# tviic2d6mddr register map
Vendor: Cypress Semiconductor; Series: tviic2d6mddr; File version: 1.0
CPU: CM7 r0p1, little endian, MPU, FPU, VTOR, 3 interrupt priority bits
Registers are 32-bit, read-write, reset 0x0 unless marked. A register's access mark holds for its fields unless they carry their own. Offsets are from the block's base; [hi:lo] are bit positions; lines under a group give offsets from that group; {n}, {i} and the like mark numbered series; 'fields as' and 'values as' point back to an identical list.

## VIDEOSS0 (part 6 of 18) — Video and Graphics Subsystem IP
Base 0x40A00000
0x80000 VIDEOIO group — Video I/O Core
  0x00 SUBIO group — Sub Interface
    0x10000 COMPENG group — Composition Engine
      0x2C00 EXTDST4 group — ExtDst #4 (Safety)
        0x0C STATUS — External Destination Unit current status
          [0] CNT_ERR_STS — Pixel count error
        0x10 CONTROLWORD ro reset not defined — Value of last received control word
          [31:0] CW_VAL
        0x14 CURPIXELCNT ro reset not defined — pixel count of currently running frame
          [31:16] C_YVAL — value of vertical line counter, internal counter counting from max-1 to 0
          [15:0] C_XVAL — value of horizontal pixel counter, internal counter counting from max-1 to 0
        0x18 LASTPIXELCNT ro reset not defined — pixel count between last two control words
          [31:16] L_YVAL — value of vertical line counter
          [15:0] L_XVAL — value of horizontal pixel counter
        0x1C PERFCOUNTER ro — Performance counter result
          [31:0] PERFRESULT — Returns the performance counter value. Returns number of cycles of the last frame on the input. To calculate the performance divide the known number of pixels of the frame by this number. For debug purposes only, read when stable only, otherwise read data might be corrupted.
      0x3000 CONSTFRAME1 group — ConstFrame #1 (Content)
        0x00 STATICCONTROL — ConstFrame unit static control register
          [0] SHDEN — Enables shadowing of all RWS type registers (0=write_through, 1=shadowed).
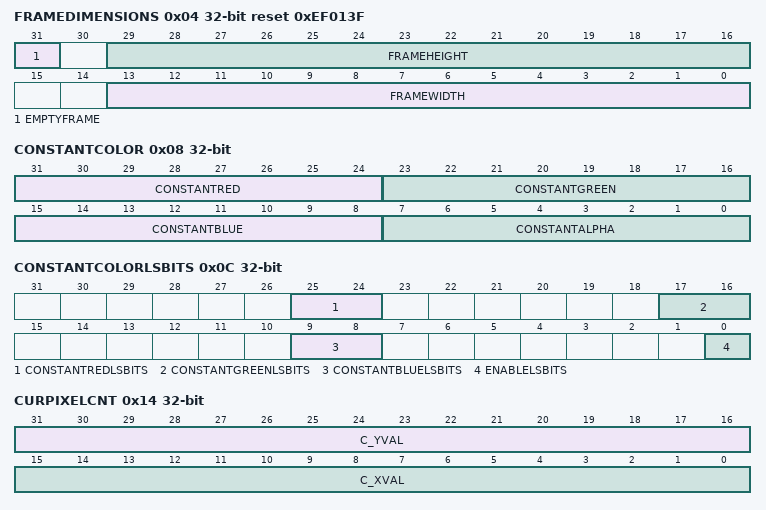
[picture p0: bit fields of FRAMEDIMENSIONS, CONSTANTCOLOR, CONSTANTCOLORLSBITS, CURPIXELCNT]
        0x04 FRAMEDIMENSIONS reset 0xEF013F — Output frame dimensions.
          [31] EMPTYFRAME — When enabled output frame is empty. FrameWidth/Height settings have no effect then. Can be used to load shadows or to generate synchronization signals only (frame/sequence complete).
          [29:16] FRAMEHEIGHT — Frame height in pixels minus one.
          [13:0] FRAMEWIDTH — Frame width in pixels minus one.
        0x08 CONSTANTCOLOR — 8-bit constant frame color components.
          [31:24] CONSTANTRED — Red component.
          [23:16] CONSTANTGREEN — Green component.
          [15:8] CONSTANTBLUE — Blue component.
          [7:0] CONSTANTALPHA — Alpha component.
        0x0C CONSTANTCOLORLSBITS — LSBits for 10-bit constant frame color components (optional).
          [25:24] CONSTANTREDLSBITS — LSBits of 10-bit red component.
          [17:16] CONSTANTGREENLSBITS — LSBits of 10-bit green component.
          [9:8] CONSTANTBLUELSBITS — LSBits of 10-bit blue component.
          [0] ENABLELSBITS — If enabled, the two least significant bits of 10-bit color components are taken from this register. Otherwise the two most significant bits from 8-bit values in ConstantColor register are taken.
        0x10 CONTROLTRIGGER wo reset not defined — ConstFrame unit trigger register
          [0] SHDTOKGEN — Writing a 1 to this will load shadow registers into the active configuration with the next start of frame and send a shadow load token to subsequent units.
        0x14 START wo reset not defined — ConstFrame unit start register
          [0] START — Writing a one starts processing, it is recommended to use this for debug purposes only.
      0x3400 EXTDST1 group — ExtDst #1 (Content)
        0x00 STATICCONTROL reset 0x100 — External Destination static control register
          [12] PERFCOUNTMODE — Value 1 enables performance counter mode, which does not generate an output frame but processes input data as fast as possible instead. Can be used to determine the maximum possible read-out performance of display buffers.
          [8] KICK_MODE — Operation mode of generated kick signal
            0=SOFTWARE (kick generation by KICK field only); 1=EXTERNAL (kick signal from external allowed)
          [0] SHDEN — Enables shadowing of all RWS type registers (0=write_through, 1=shadowed).
        0x04 CONTROL — External Destination shadowed control register
          [0] GAMMAAPPLYENABLE — Enable gamma conversion stage to apply gamma function. This gamma function converts the pixel data from linear color space to non-linear color space before they are output.
        0x08 SOFTWAREKICK wo reset not defined — External Destination software kick
          [0] KICK — Software kick, forces a kick signal independent of KICK_MODE. Write 1 to send kick.
        0x0C STATUS — External Destination Unit current status
          [0] CNT_ERR_STS — Pixel count error
        0x10 CONTROLWORD ro reset not defined — Value of last received control word
          [31:0] CW_VAL
        0x14 CURPIXELCNT ro reset not defined — pixel count of currently running frame
          fields as VIDEOIO.SUBIO.COMPENG.EXTDST4.CURPIXELCNT
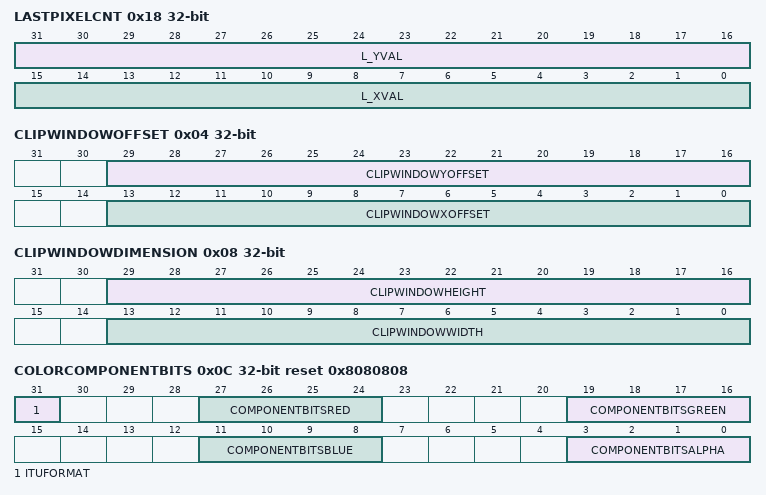
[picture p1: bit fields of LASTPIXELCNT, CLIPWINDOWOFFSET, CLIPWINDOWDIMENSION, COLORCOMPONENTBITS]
        0x18 LASTPIXELCNT ro reset not defined — pixel count between last two control words
          fields as VIDEOIO.SUBIO.COMPENG.EXTDST4.LASTPIXELCNT
        0x1C PERFCOUNTER ro — Performance counter result
          fields as VIDEOIO.SUBIO.COMPENG.EXTDST4.PERFCOUNTER
      0x3800 CONSTFRAME5 group — ConstFrame #5 (Safety)
        0x00 STATICCONTROL — ConstFrame unit static control register
          fields as VIDEOIO.SUBIO.COMPENG.CONSTFRAME1.STATICCONTROL
        0x04 FRAMEDIMENSIONS reset 0xEF013F — Output frame dimensions.
          fields as VIDEOIO.SUBIO.COMPENG.CONSTFRAME1.FRAMEDIMENSIONS
        0x08 CONSTANTCOLOR — 8-bit constant frame color components.
          fields as VIDEOIO.SUBIO.COMPENG.CONSTFRAME1.CONSTANTCOLOR
        0x0C CONSTANTCOLORLSBITS — LSBits for 10-bit constant frame color components (optional).
          fields as VIDEOIO.SUBIO.COMPENG.CONSTFRAME1.CONSTANTCOLORLSBITS
        0x10 CONTROLTRIGGER wo reset not defined — ConstFrame unit trigger register
          fields as VIDEOIO.SUBIO.COMPENG.CONSTFRAME1.CONTROLTRIGGER
        0x14 START wo reset not defined — ConstFrame unit start register
          fields as VIDEOIO.SUBIO.COMPENG.CONSTFRAME1.START
      0x3C00 EXTDST5 group — ExtDst #5 (Safety)
        0x00 STATICCONTROL reset 0x100 — External Destination static control register
          fields as VIDEOIO.SUBIO.COMPENG.EXTDST1.STATICCONTROL
        0x04 CONTROL — External Destination shadowed control register
          fields as VIDEOIO.SUBIO.COMPENG.EXTDST1.CONTROL
        0x08 SOFTWAREKICK wo reset not defined — External Destination software kick
          fields as VIDEOIO.SUBIO.COMPENG.EXTDST1.SOFTWAREKICK
        0x0C STATUS — External Destination Unit current status
          [0] CNT_ERR_STS — Pixel count error
        0x10 CONTROLWORD ro reset not defined — Value of last received control word
          [31:0] CW_VAL
        0x14 CURPIXELCNT ro reset not defined — pixel count of currently running frame
          fields as VIDEOIO.SUBIO.COMPENG.EXTDST4.CURPIXELCNT
        0x18 LASTPIXELCNT ro reset not defined — pixel count between last two control words
          fields as VIDEOIO.SUBIO.COMPENG.EXTDST4.LASTPIXELCNT
        0x1C PERFCOUNTER ro — Performance counter result
          fields as VIDEOIO.SUBIO.COMPENG.EXTDST4.PERFCOUNTER
      0x4000 EXTSRC4 group — ExtSrc #0 (Capture)
        0x00 STATICCONTROL — ExtSrc static control register
          [8] STARTSEL — Start select selects the mode to start processing operations.
            0=INPUT (Free running mode, use the incoming command word as trigger to start processing.); 1=LOCAL (Keep to local start configuration, use external kick or SW trigger to start processing. The behavior is similar to fetch units.)
          [0] SHDEN — Enables shadowing of all RWS type registers (0=write_through, 1=shadowed).
        0x04 CLIPWINDOWOFFSET — Clip window offset, to generate a clipping of the frame. It has to be within the input frame.
          [29:16] CLIPWINDOWYOFFSET — Clip window offset in Y direction, relative to the frame origin.
          [13:0] CLIPWINDOWXOFFSET — Clip window offset in X direction, relative to the frame origin.
        0x08 CLIPWINDOWDIMENSION — Define the clip window dimension. If the clip window feature is enabled this dimension is used for the new frame dimension. Note that the clip window has to be smaller or equal to the original frame dimensions. The new frame has to be within the active area of the original frame.
          [29:16] CLIPWINDOWHEIGHT — Clip window height in pixels minus one.
          [13:0] CLIPWINDOWWIDTH — Clip window width in pixels minus one.
        0x0C COLORCOMPONENTBITS reset 0x8080808 — Color component size of raw input data. Please note that the width must be equal or lower than the output width.
          [31] ITUFORMAT — When ComponentBitsRed/Green/Blue is set to 10 and this mode enabled (value 1), then input format is considered 8.2 instead of 10.0 bits (max color is 1020 instead of 1023). This is compliant to ITU 656 standard.
          [27:24] COMPONENTBITSRED — Component size of red channel [0-10].
          [19:16] COMPONENTBITSGREEN — Component size of green channel [0-10].
          [11:8] COMPONENTBITSBLUE — Component size of blue channel [0-10].
          [3:0] COMPONENTBITSALPHA — Component size of alpha channel [0-8].
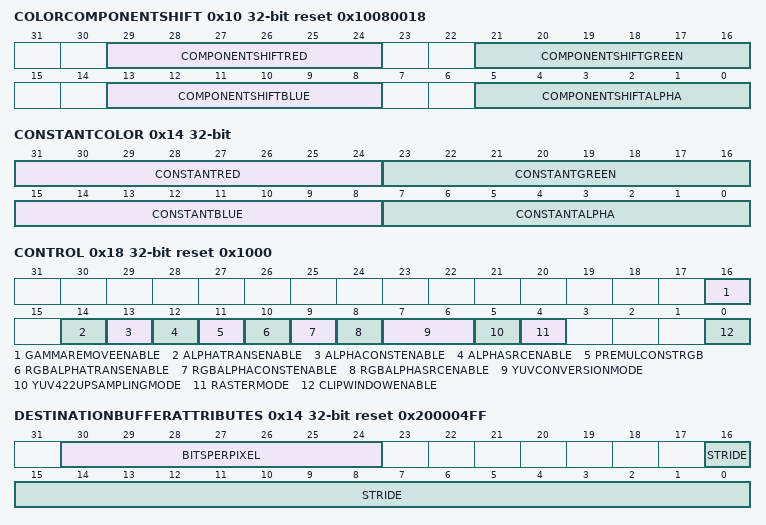
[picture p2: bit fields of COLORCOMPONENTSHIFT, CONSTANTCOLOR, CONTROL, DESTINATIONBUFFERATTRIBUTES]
        0x10 COLORCOMPONENTSHIFT reset 0x10080018 — Color component offset of raw input data.
          [29:24] COMPONENTSHIFTRED — Offset for red component.
          [21:16] COMPONENTSHIFTGREEN — Offset for green component.
          [13:8] COMPONENTSHIFTBLUE — Offset for blue component.
          [5:0] COMPONENTSHIFTALPHA — Offset for alpha component.
        0x14 CONSTANTCOLOR
          [31:24] CONSTANTRED — Red or Y (luma).
          [23:16] CONSTANTGREEN — Green or U (chroma).
          [15:8] CONSTANTBLUE — Blue or V (chroma).
          [7:0] CONSTANTALPHA — Alpha.
        0x18 CONTROL reset 0x1000 — Common control settings.
          [16] GAMMAREMOVEENABLE — Value 1 enables the stage to remove a gamma from RGB components.
          [14] ALPHATRANSENABLE — Value 1 enables transparent alpha for computing the output alpha. When disabled transparent alpha is set to 1.
          [13] ALPHACONSTENABLE — Value 1 enables constant alpha for computing the output alpha. When disabled constant alpha is set to 1.
          [12] ALPHASRCENABLE — Value 1 enables source alpha for computing the output alpha. When disabled source alpha is set to 1.
          [11] PREMULCONSTRGB — When enabled (value 1) the values given by ConstantRed/Green/Blue are used instead of alpha for source RGB pre-multiply. Settings RGBAlphaSrc/Const/TransEnable have no effect then.
          [10] RGBALPHATRANSENABLE — Value 1 enables transparent alpha (0 or 1 depending on RGB matching ConstantColor setting) for RGB pre-multiply. When disabled transparent alpha is set to 1.
          [9] RGBALPHACONSTENABLE — Value 1 enables constant alpha (ConstAlpha field) for RGB pre-multiply. When disabled constant alpha is set to 1.
          [8] RGBALPHASRCENABLE — Value 1 enables source alpha (extracted from input stream) for RGB pre-multiply. When disabled source alpha is set to 1.
          [7:6] YUVCONVERSIONMODE — Enables different kind of YUV to RGB conversions.
            0=OFF (No conversion. Input data must be RGB.); 1=ITU601 (Conversion from YCbCr (YUV) to RGB according to ITU recommendation BT.601-6 (standard definition TV). Input range is 16..235 for Y and 16..240 for U/V.); 2=ITU601_FR (Conversion from YCbCr (YUV) to RGB according to ITU recommendation BT.601-6, but assuming full range YUV inputs (0..255). Most typically used for computer graphics (e.g. for JPEG encoding).); 3=ITU709 (Conversion from YCbCr (YUV) to RGB according to ITU recommendation BT.709-5 part 2 (high definition TV). Input range is 16..235 for Y and 16..240 for U/V.)
          [5] YUV422UPSAMPLINGMODE — Selects a method for horizontal up-sampling when RasterMode is YUV422.
            0=REPLICATE (Replicate mode for interspersed samples (UV samples between Y samples).); 1=INTERPOLATE (Interpolate mode for coaligned samples (UV samples at Y sample positions).)
          [4] RASTERMODE — Selects a method how generate output samples from input stream.
            0=NORMAL (Input stream is RGB(A) or YUV 4:4:4.); 1=YUV422 (Input stream is packed YUV 4:2:2.)
          [0] CLIPWINDOWENABLE — Value 1 enables the clip window feature.
        0x1C CONTROLTRIGGER wo reset not defined — ExtSrc unit trigger token generation
          [0] SHDTOKGEN — Write a 1 to this field for the extsrc unit to perform a shadow load with the next start of operation and set the rld bit in the start of frame control word (generate shadow load token for subsequent units).
        0x20 START wo reset not defined — ExtSrc unit start register
          [0] START — Writing a one starts processing, use this only for debug purposes.
      0x4400 STORE4 group — Store #0 (Capture)
        0x00 STATICCONTROL — Store unit static control register.
          [8] BASEADDRESSAUTOUPDATE — If enabled (value 1) the base address is automatically updated at the start of each frame. This update is then executed independently of the ShdEn setting. When disabled ShdEn controls the update of the base address operation register.
          [4] SINGLEFRAMEOPERATION — If this field and ShdEn are enabled, only frames with reload bit in command word are written to AXI, other frames are still consumed. If disabled all frames are writen to AXI
          [0] SHDEN — Enables shadowing of all RWS type registers (0=write_through, 1=shadowed).
        0x04 BURSTBUFFERMANAGEMENT reset 0x400 — Burst Buffer setup register.
          [12:8] SETBURSTLENGTH — Set this to the burst length that should be used on the AXI interface. Please note that SetBurstLength has to be smaller or equal to MaxBurstLength. Only a power of two may be specified as burst length. Please set this to at least 2 for 64bit pixels, otherwise performance will suffer.
        0x08 RINGBUFSTARTADDR — Ring buffer setup for destination.
          [31:0] RINGBUFSTARTADDR — Start address of the ring buffer. Must be aligned to SetBurstLength x 8 bytes.
        0x0C RINGBUFWRAPADDR — Ring buffer setup for destination.
          [31:0] RINGBUFWRAPADDR — End address of the ring buffer (last byte of the buffer plus one).
        0x10 BASEADDRESS — Destination buffer base address.
          [31:0] BASEADDRESS — Byte aligned start address of the destination buffer. For 32 bit pixels BaseAddress[1:0] must be set 0 and for 16 bit pixels BaseAddress[0] must be set 0.
        0x14 DESTINATIONBUFFERATTRIBUTES reset 0x200004FF
          [30:24] BITSPERPIXEL — Size of a pixel in the destination buffer in bits. Has to be a power of two, 18 or 24. When 64 bit is selected, input pixels are converted into a 32 bit value that is replicated into low and high word of the 64 bit output. Set SetBurstLength at least to 2 in that case to get best possible performance.
          [16:0] STRIDE — Destination buffer stride in bytes minus one, used for address generation. For a pixel width of 32 bits Stride has to be dividable by 4 and given minus one and for a pixel width of 16 bit Stride has to be dividable by two and given minus one.
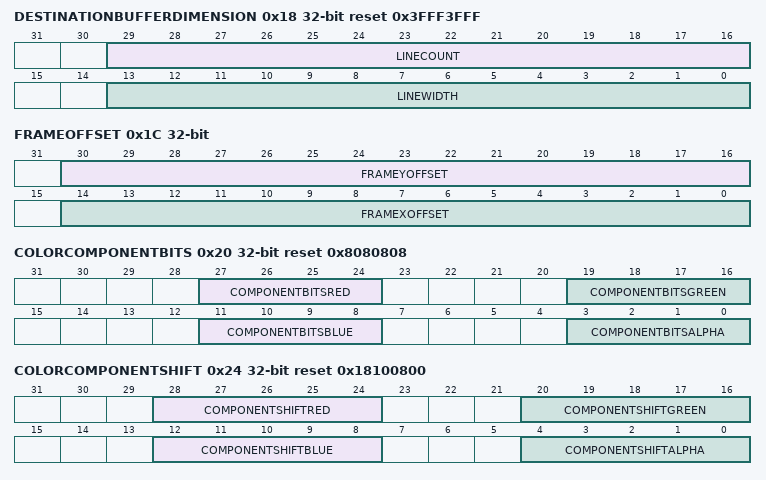
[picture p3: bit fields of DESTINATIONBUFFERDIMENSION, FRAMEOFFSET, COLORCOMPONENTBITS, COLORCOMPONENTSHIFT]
        0x18 DESTINATIONBUFFERDIMENSION reset 0x3FFF3FFF
          [29:16] LINECOUNT — Number of lines of the destination buffer in pixels minus one.
          [13:0] LINEWIDTH — Width of the destination buffer in pixels minus one.
        0x1C FRAMEOFFSET — Offset between destination frame and buffer.
          [30:16] FRAMEYOFFSET — Vertical offset (Y). (format is signed integer)
          [14:0] FRAMEXOFFSET — Horizontal offset (X). FrameXOffset * BitsPerPixel must be byte aligned. The same applies to the Store unit's input frame width * BitsPerPixel. (format is signed integer)
        0x20 COLORCOMPONENTBITS reset 0x8080808 — Color component size of destination buffer
          [27:24] COMPONENTBITSRED — Red/Y component bits.
          [19:16] COMPONENTBITSGREEN — Green/U component bits.
          [11:8] COMPONENTBITSBLUE — Blue/V component bits.
          [3:0] COMPONENTBITSALPHA — Alpha component bits.
        0x24 COLORCOMPONENTSHIFT reset 0x18100800 — Color component offset of destination buffer.
          [28:24] COMPONENTSHIFTRED — Red/Y component shift.
          [20:16] COMPONENTSHIFTGREEN — Green/U component shift.
          [12:8] COMPONENTSHIFTBLUE — Blue/V component shift.
          [4:0] COMPONENTSHIFTALPHA — Alpha component shift.
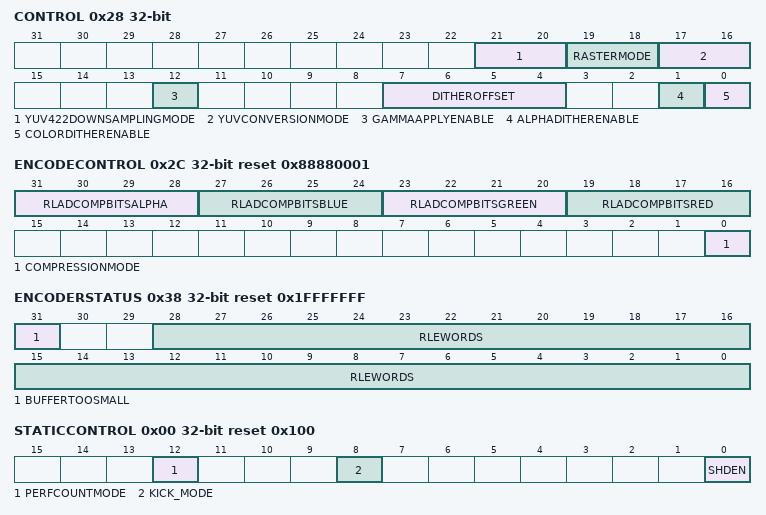
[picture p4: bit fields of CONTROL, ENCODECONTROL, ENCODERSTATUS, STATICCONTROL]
        0x28 CONTROL — Store unit dynamic control register
          [21:20] YUV422DOWNSAMPLINGMODE — Selects a method for horizontal down-sampling when RasterMode is YUV422.
            0=NEAREST (Nearest mode. Discards all odd samples, outputs even samples.); 1=COALIGNED (Linear coaligned mode. 3 nearest UV samples are combined in linear filter to get one output sample.); 2=INTERSPERSED (Linear interspersed mode. 2 nearest UV samples are combined in linear filter to get one output sample.)
          [19:18] RASTERMODE — Selects a method for destination buffer data from input pixels.
            0=NORMAL (RGBA or YUV 4:4:4 pixel buffer.); 1=YUV422 (Packed YUV 4:2:2 pixel buffer. Effect is that U samples are written for pixels with even and V samples for odd column index only. So BitsPerPixel must be set to the size that a pair of YU or YV has in memory (most typically 16 bits). All correlated widths and horizontal offsets must be even.); 2=ENCODE (RLAD compressed bit stream.)
          [17:16] YUVCONVERSIONMODE — Enables different kind of RGB to YUV conversions.
            values as VIDEOIO.SUBIO.COMPENG.EXTSRC4.CONTROL.YUVCONVERSIONMODE
          [12] GAMMAAPPLYENABLE — Enable gamma conversion stage to apply gamma function. This gamma function converts the pixel data from linear color space to non-linear color space before writing it to AXI.
          [7:4] DITHEROFFSET — Dither offset that is additionally applied to the spatial offset, which is internally generated from the pixel position. Can be used by SW to generate image sequences with temporal dithering.
          [1] ALPHADITHERENABLE — Controls whether spatial dithering (value 1) or LSB truncation (value 0) is used when ComponentBitsAlpha is smaller than 8 bits.
          [0] COLORDITHERENABLE — Controls whether spatial dithering (value 1) or LSB truncation (value 0) is used when ComponentBitsRed/Green/Blue is smaller than 10 bits.
        0x2C ENCODECONTROL reset 0x88880001 — Control options for RLAD compression.
          [31:28] RLADCOMPBITSALPHA — Maximum for average number of bits per compressed pixel for Alpha channel.
          [27:24] RLADCOMPBITSBLUE — Maximum for average number of bits per compressed pixel for Blue or V (chroma) channel.
          [23:20] RLADCOMPBITSGREEN — Maximum for average number of bits per compressed pixel for Green or U (chroma) channel.
          [19:16] RLADCOMPBITSRED — Maximum for average number of bits per compressed pixel for Red or Y (luma) channel.
          [0] COMPRESSIONMODE — Algorithm to use for compression.
            0=RLAD (Run-Length Adaptive Dithering (lossy compression).); 1=RLAD_UNIFORM (Run-Length Adaptive Dithering (lossy compression; uniform package size).)
        0x30 DESTINATIONBUFFERLENGTH — Destination buffer length for compressed data.
          [28:0] RLEWORDSMAX
        0x34 START wo reset not defined — Store unit start register
          [0] START — Writing a one starts processing of the pixel engine.
        0x38 ENCODERSTATUS reset 0x1FFFFFFF — Status information of the RLAD encoder.
          [31] BUFFERTOOSMALL — The buffer size given by RLEWordsMax is too small. Not the complete input frame could be encoded.
          [28:0] RLEWORDS ro — Number of 32-bit words minus one that was used for the compressed buffer.
        0x3C WRITEADDRESS ro — Ring buffer synchronization.
          [31:0] WRITEADDRESS — Last burst address that was written to the destination buffer.
        0x40 FRAMEPROPERTIES ro — Ring buffer synchronization.
          [0] FIELDID — Field identifier for interlaced video streams (0/1 = even/odd line indices of progressive frame). Status is updated with begin of a new field.
        0x44 BURSTBUFFERPROPERTIES ro reset not defined — Burst Buffer Property register
          [12:8] MAXBURSTLENGTH — Maximum Burst Length that can be configured.
        0x48 LASTCONTROLWORD ro — Shows the last control word received
          [31:0] L_VAL — Shows the last control word received from the pixel engine. If a 39 bit pixel channel is connected, the mapping is as follows: l_val[31:0] = { data[37:22], data[19:12], data[9:2] }. For debug purposes only, read when stable only, otherwise read data might be corrupted.
        0x4C PERFCOUNTER ro — Performance counter result
          [31:0] PERFRESULT — Returns the performance counter value. Please note that a sw reset during a frame can potentially produce invalid results in the first frame afterwards. For debug purposes only, read when stable only, otherwise read data might be corrupted.
      0x4800 FETCHLAYER0 group — FetchLayer #0 (Display)
        0x00 STATICCONTROL reset 0xFF000002 — Common static control options.
          [31:24] SHDLDREQSTICKY — Shadow load request flags for each layer (always load). See description of register TriggerEnable for further information.
          [23:16] BASEADDRESSAUTOUPDATE — Enable flag for continuous shadow load of BaseAddress field for each layer (layer index = bit index). When set to 1 the active BaseAddress configuration is loaded from shadow at start of each frame. This update is then executed independently from other RWS type fields. ShdEn must be enabled for this mode. When the flag is enabled for layer 0, also the FieldId0 shadow is automatically loaded.
          [1] LBHSHDEN — Enables shadowing of LBH configuration signals.
          [0] SHDEN — Enables shadowing of all RWS type registers (0=write_through, 1=shadowed).
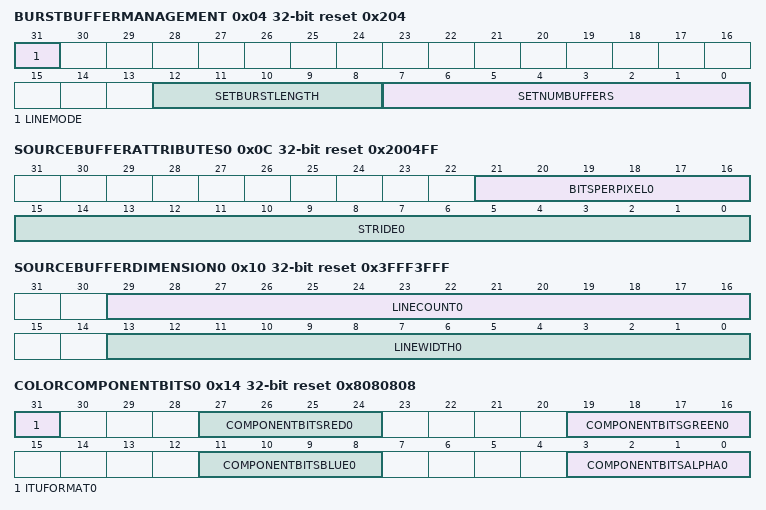
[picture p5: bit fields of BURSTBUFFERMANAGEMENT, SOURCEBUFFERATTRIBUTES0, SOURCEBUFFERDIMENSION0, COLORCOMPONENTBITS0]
        0x04 BURSTBUFFERMANAGEMENT reset 0x204 — AXI interface buffer management register
          [31] LINEMODE — Fetch buffer cache control.
            0=DISPLAY (Mandatory setting for operation in the Display Controller. Works also for Blit Engine with marginal performance impact.); 1=BLIT (Recommended setting for operation in the Blit Engine.)
          [12:8] SETBURSTLENGTH — Set this to the burst length that should be used on the AXI interface. SetNumBuffers * SetBurstLength has to be smaller or equal to ManagedBurstBuffers * BurstLengthForMaxBuffers and that bursts larger than 16 are not possible on the axi interface. Only a power of two may be specified as burst length.
          [7:0] SETNUMBUFFERS — Set this to the number of bursts that should be buffered. SetNumBuffers has to be smaller or equal to ManagedBurstBuffers and SetNumBuffers * SetBurstLength has to be smaller or equal to ManagedBurstBuffers * BurstLengthForMaxBuffers. Must be a power of 2. The minimum allowed settings is 4 except for the FetchEco derivate which has a minimum allowed setting of 2.
        0x08 BASEADDRESS0 — Source buffer base address of layer 0.
          [31:0] BASEADDRESS0 — Byte aligned start address of the layer source buffer. For a pixel width of 32 bits or DECODE operations BaseAddress bits 1 downto 0 have to be 0 and for a pixel width of 16 bit BaseAddress[0] has to be 0.
        0x0C SOURCEBUFFERATTRIBUTES0 reset 0x2004FF — Source buffer attributes for layer 0.
          [21:16] BITSPERPIXEL0 — Number of bits per pixel in the source buffer. Must be 1, 2, 4, 8, 16, 18, 24 or 32. [Exception] FetchEco does not support 18 and 24.
          [15:0] STRIDE0 — Source buffer stride of the layer in bytes minus one, used for address generation. For a pixel width of 32 bits Stride has to be dividable by 4 and given minus one and for a pixel width of 16 bit Stride has to be dividable by two and given minus one.
        0x10 SOURCEBUFFERDIMENSION0 reset 0x3FFF3FFF — Source buffer dimension of layer 0.
          [29:16] LINECOUNT0 — Number of lines of the source buffer of the layer minus one.
          [13:0] LINEWIDTH0 — Width of the source buffer of the layer in pixels minus one.
        0x14 COLORCOMPONENTBITS0 reset 0x8080808 — Size of color components for RGB, YUV and index formats (layer 0).
          [31] ITUFORMAT0 — When ComponentBitsRed/Green/Blue is set to 10 and this mode enabled (value 1), then input format is considered 8.2 instead of 10.0 bits (max color is 1020 instead of 1023). This is compliant to ITU 656 standard.
          [27:24] COMPONENTBITSRED0 — Red, Y (luma) and palette index.
          [19:16] COMPONENTBITSGREEN0 — Green and U (chroma).
          [11:8] COMPONENTBITSBLUE0 — Blue and V (chroma).
          [3:0] COMPONENTBITSALPHA0 — Alpha.
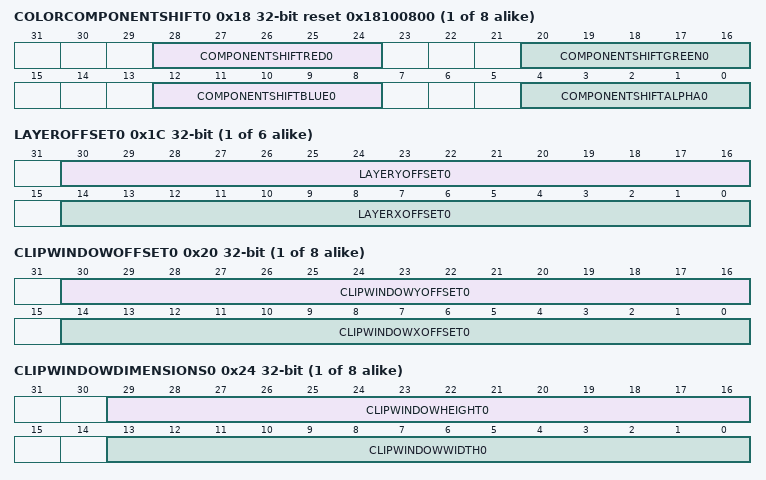
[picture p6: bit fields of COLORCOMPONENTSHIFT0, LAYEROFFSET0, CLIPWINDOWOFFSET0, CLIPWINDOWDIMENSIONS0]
        {0x18+0x28*m} COLORCOMPONENTSHIFT{m} reset 0x18100800 (m=0..7) — Bit position of color components for RGB, YUV and index formats (layer {m}).
          [28:24] COMPONENTSHIFTRED{m} — Red, Y (luma) and palette index.
          [20:16] COMPONENTSHIFTGREEN{m} — Green and U (chroma).
          [12:8] COMPONENTSHIFTBLUE{m} — Blue and V (chroma).
          [4:0] COMPONENTSHIFTALPHA{m} — Alpha.
        {0x1C+0x28*m} LAYEROFFSET{m} (m=0..5) — Position of layer {m} within the destination frame.
          [30:16] LAYERYOFFSET{m} — Vertical offset (Y). (format is signed integer)
          [14:0] LAYERXOFFSET{m} — Horizontal offset (X). (format is signed integer)
        {0x20+0x28*m} CLIPWINDOWOFFSET{m} (m=0..7) — Clip window position for layer {m}.
          [30:16] CLIPWINDOWYOFFSET{m} — Vertical position (Y). (format is signed integer)
          [14:0] CLIPWINDOWXOFFSET{m} — Horizontal position (X). (format is signed integer)
        {0x24+0x28*m} CLIPWINDOWDIMENSIONS{m} (m=0..7) — Clip window size for layer {m}.
          [29:16] CLIPWINDOWHEIGHT{m} — Height.
          [13:0] CLIPWINDOWWIDTH{m} — Width.
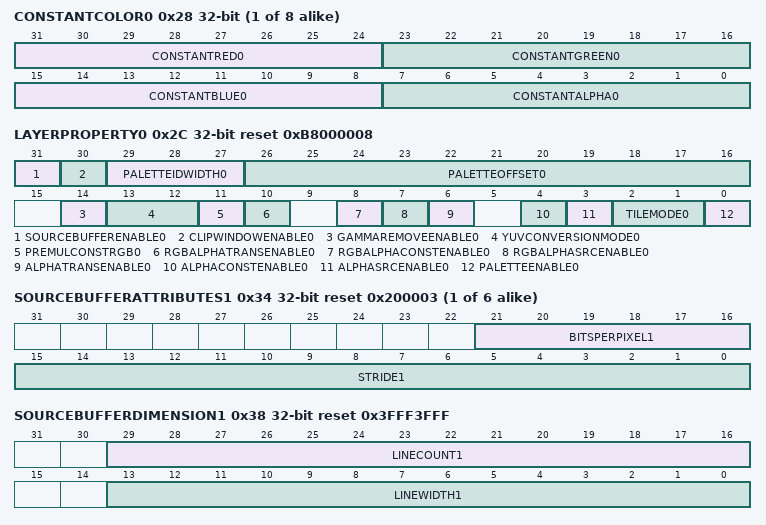
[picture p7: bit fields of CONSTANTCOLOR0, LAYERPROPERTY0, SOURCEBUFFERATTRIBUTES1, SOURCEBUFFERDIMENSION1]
        {0x28+0x28*m} CONSTANTCOLOR{m} (m=0..7) — Constant color for layer {m}.
          [31:24] CONSTANTRED{m} — Red and Y (luma).
          [23:16] CONSTANTGREEN{m} — Green and U (chroma).
          [15:8] CONSTANTBLUE{m} — Blue and V (chroma).
          [7:0] CONSTANTALPHA{m} — Alpha.
        0x2C LAYERPROPERTY0 reset 0xB8000008 — Common properties of layer 0.
          [31] SOURCEBUFFERENABLE0 — Value 1 enables the source buffer for this layer. When disabled the tiling color is used only (TileMode TILE_PAD not allowed).
          [30] CLIPWINDOWENABLE0 — Value 1 enables the clip window for this layer. Pixels outside the clip window get the clip color, pixels inside the source or tiling color.
          [29:27] PALETTEIDWIDTH0 — Number minus one of least significant bits of pixel data read from the source buffer that are used as index value for color palette look-up.
          [26:16] PALETTEOFFSET0 — Palette may contain multiple areas. This offset shows to the starting position of the currently used area.
          [14] GAMMAREMOVEENABLE0 — Value 1 enables the stage to remove a gamma from RGB components.
          [13:12] YUVCONVERSIONMODE0 — Enables different kind of YUV to RGB conversions.
            0=OFF (No conversion.); 1=ITU601 (Conversion from YCbCr (YUV) to RGB according to ITU recommendation BT.601-6 (standard definition TV). Input range is 16..235 for Y and 16..240 for U/V.); 2=ITU601_FR (Conversion from YCbCr (YUV) to RGB according to ITU recommendation BT.601-6, but assuming full range YUV inputs (0..255). Most typically used for computer graphics (e.g. for JPEG encoding).); 3=ITU709 (Conversion from YCbCr (YUV) to RGB according to ITU recommendation BT.709-5 part 2 (high definition TV). Input range is 16..235 for Y and 16..240 for U/V.)
          [11] PREMULCONSTRGB0 — When enabled (value 1) the values given by ConstantRed/Green/Blue are used instead of alpha for source RGB pre-multiply. Settings RGBAlphaSrc/Const/Mask/TransEnable have no effect then.
          [10] RGBALPHATRANSENABLE0 — Value 1 enables transparent alpha (0 or 1 depending on RGB matching ConstantColor setting) for RGB pre-multiply. When disabled transparent alpha is set to 1.
          [8] RGBALPHACONSTENABLE0 — Value 1 enables constant alpha (ConstAlpha fields) for RGB pre-multiply. When disabled constant alpha is set to 1.
          [7] RGBALPHASRCENABLE0 — Value 1 enables source alpha (stored together with color component in the source buffer) for RGB pre-multiply. When disabled source alpha is set to 1.
          [6] ALPHATRANSENABLE0 — Value 1 enables transparent alpha for computing the output alpha. When disabled transparent alpha is set to 1.
          [4] ALPHACONSTENABLE0 — Value 1 enables constant alpha for computing the output alpha. When disabled constant alpha is set to 1.
          [3] ALPHASRCENABLE0 — Value 1 enables source alpha for computing the output alpha. When disabled source alpha is set to 1.
          [2:1] TILEMODE0 — Select the tile mode for pixels outside the source buffer. Clip color (0,0,0,0) takes precedence if a pixel becomes subject to both tiling and clipping.
            0=TILE_FILL_ZERO (Use zero value); 1=TILE_FILL_CONSTANT (Use constant color register value); 2=TILE_PAD (Use closest pixel from source buffer. Must not be used for DECODE or YUV422 operations or when SourceBufferEnable is 0.); 3=TILE_PAD_ZERO (Use closest pixel from source buffer but zero for alpha component. Must not be used for DECODE or YUV422 operations or when SourceBufferEnable is 0.)
          [0] PALETTEENABLE0 — Enables (value = 1) a color palette with 8 bits input and 24 bits output. Lower bits of the lookup index are read from memory (PaletteIdWidth0), upper bits are set to index of this layer. Palette output is extended by upper bits of index word read from memory (e.g. to store alpha together with index). Result is mapped to color channels according to ColorComponentBits/Shift settings.
        {0x8+0x28*m} BASEADDRESS{m} (m=1..7) — Source buffer base address of layer {m}.
          [31:0] BASEADDRESS{m} — See BaseAddress0.
        {0xC+0x28*m} SOURCEBUFFERATTRIBUTES{m} reset 0x200003 (m=1..6) — Source buffer attributes for layer {m}.
          [21:16] BITSPERPIXEL{m} — See BitsPerPixel0.
          [15:0] STRIDE{m} — See Stride0.
        0x38 SOURCEBUFFERDIMENSION1 reset 0x3FFF3FFF — Source buffer dimensions of layer 1,
          [29:16] LINECOUNT1 — See LineCount0.
          [13:0] LINEWIDTH1 — See LineWidth0.
